AUTOSAR XML (schema 00044)
package /E40_Platform_System_SystemPackage/Components
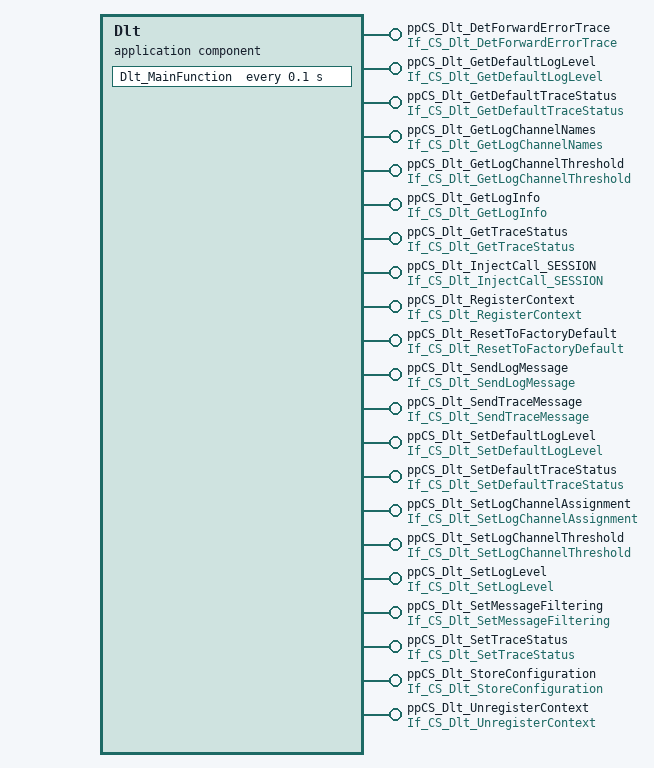
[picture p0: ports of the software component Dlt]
  application sw component type Dlt
    21 x provide port:
      ppCS_Dlt_DetForwardErrorTrace: server-com-spec{operation=DetForwardErrorTrace, queue-length=1}, provided-interface=If_CS_Dlt_DetForwardErrorTrace
      ppCS_Dlt_GetDefaultLogLevel: server-com-spec{operation=GetDefaultLogLevel, queue-length=1}, provided-interface=If_CS_Dlt_GetDefaultLogLevel
      ppCS_Dlt_GetDefaultTraceStatus: server-com-spec{operation=GetDefaultTraceStatus, queue-length=1}, provided-interface=If_CS_Dlt_GetDefaultTraceStatus
      ppCS_Dlt_GetLogChannelNames: server-com-spec{operation=GetLogChannelNames, queue-length=1}, provided-interface=If_CS_Dlt_GetLogChannelNames
      ppCS_Dlt_GetLogChannelThreshold: server-com-spec{operation=GetLogChannelThreshold, queue-length=1}, provided-interface=If_CS_Dlt_GetLogChannelThreshold
      ppCS_Dlt_GetLogInfo: server-com-spec{operation=GetLogInfo, queue-length=1}, provided-interface=If_CS_Dlt_GetLogInfo
      ppCS_Dlt_GetTraceStatus: server-com-spec{operation=GetTraceStatus, queue-length=1}, provided-interface=If_CS_Dlt_GetTraceStatus
      ppCS_Dlt_InjectCall_SESSION: server-com-spec{operation=InjectCall_SESSION, queue-length=1}, provided-interface=If_CS_Dlt_InjectCall_SESSION
      ppCS_Dlt_RegisterContext: server-com-spec{operation=RegisterContext, queue-length=1}, provided-interface=If_CS_Dlt_RegisterContext
      ppCS_Dlt_ResetToFactoryDefault: server-com-spec{operation=ResetToFactoryDefault, queue-length=1}, provided-interface=If_CS_Dlt_ResetToFactoryDefault
      ppCS_Dlt_SendLogMessage: server-com-spec{operation=SendLogMessage, queue-length=1}, provided-interface=If_CS_Dlt_SendLogMessage
      ppCS_Dlt_SendTraceMessage: server-com-spec{operation=SendTraceMessage, queue-length=1}, provided-interface=If_CS_Dlt_SendTraceMessage
      ppCS_Dlt_SetDefaultLogLevel: server-com-spec{operation=SetDefaultLogLevel, queue-length=1}, provided-interface=If_CS_Dlt_SetDefaultLogLevel
      ppCS_Dlt_SetDefaultTraceStatus: server-com-spec{operation=SetDefaultTraceStatus, queue-length=1}, provided-interface=If_CS_Dlt_SetDefaultTraceStatus
      ppCS_Dlt_SetLogChannelAssignment: server-com-spec{operation=SetLogChannelAssignment, queue-length=1}, provided-interface=If_CS_Dlt_SetLogChannelAssignment
      ppCS_Dlt_SetLogChannelThreshold: server-com-spec{operation=SetLogChannelThreshold, queue-length=1}, provided-interface=If_CS_Dlt_SetLogChannelThreshold
      ppCS_Dlt_SetLogLevel: server-com-spec{operation=SetLogLevel, queue-length=1}, provided-interface=If_CS_Dlt_SetLogLevel
      ppCS_Dlt_SetMessageFiltering: server-com-spec{operation=SetMessageFiltering, queue-length=1}, provided-interface=If_CS_Dlt_SetMessageFiltering
      ppCS_Dlt_SetTraceStatus: server-com-spec{operation=SetTraceStatus, queue-length=1}, provided-interface=If_CS_Dlt_SetTraceStatus
      ppCS_Dlt_StoreConfiguration: server-com-spec{operation=StoreConfiguration, queue-length=1}, provided-interface=If_CS_Dlt_StoreConfiguration
      ppCS_Dlt_UnregisterContext: server-com-spec{operation=UnregisterContext, queue-length=1}, provided-interface=If_CS_Dlt_UnregisterContext
    behavior IB_Dlt
      8 x operation invoked event:
        OIE_ppCS_Dlt_DetForwardErrorTrace_Dlt_DetForwardErrorTraceTrigByDetForwardErrorTrace: start-on-event=Dlt_DetForwardErrorTrace, operation=ppCS_Dlt_DetForwardErrorTrace.DetForwardErrorTrace
        OIE_ppCS_Dlt_GetDefaultLogLevel_Dlt_GetDefaultLogLevelTrigByGetDefaultLogLevel: start-on-event=Dlt_GetDefaultLogLevel, operation=ppCS_Dlt_GetDefaultLogLevel.GetDefaultLogLevel
        OIE_ppCS_Dlt_GetDefaultTraceStatus_Dlt_GetDefaultTraceStatusTrigByGetDefaultTraceStatus: start-on-event=Dlt_GetDefaultTraceStatus, operation=ppCS_Dlt_GetDefaultTraceStatus.GetDefaultTraceStatus
        OIE_ppCS_Dlt_GetLogChannelNames_Dlt_GetLogChannelNamesTrigByGetLogChannelNames: start-on-event=Dlt_GetLogChannelNames, operation=ppCS_Dlt_GetLogChannelNames.GetLogChannelNames
        OIE_ppCS_Dlt_GetLogChannelThreshold_Dlt_GetLogChannelThresholdTrigByGetLogChannelThreshold: start-on-event=Dlt_GetLogChannelThreshold, operation=ppCS_Dlt_GetLogChannelThreshold.GetLogChannelThreshold
        OIE_ppCS_Dlt_GetLogInfo_Dlt_GetLogInfoTrigByGetLogInfo: start-on-event=Dlt_GetLogInfo, operation=ppCS_Dlt_GetLogInfo.GetLogInfo
        OIE_ppCS_Dlt_GetTraceStatus_Dlt_GetTraceStatusTrigByGetTraceStatus: start-on-event=Dlt_GetTraceStatus, operation=ppCS_Dlt_GetTraceStatus.GetTraceStatus
        OIE_ppCS_Dlt_InjectCall_SESSION_Dlt_InjectCall_SESSIONTrigByInjectCall_SESSION: start-on-event=Dlt_InjectCall_SESSION, operation=ppCS_Dlt_InjectCall_SESSION.InjectCall_SESSION
      timing event TEDlt_MainFunction: start-on-event=Dlt_MainFunction, period=0.1
      13 x operation invoked event:
        OIE_ppCS_Dlt_RegisterContext_Dlt_RegisterContextTrigByRegisterContext: start-on-event=Dlt_RegisterContext, operation=ppCS_Dlt_RegisterContext.RegisterContext
        OIE_ppCS_Dlt_ResetToFactoryDefault_Dlt_ResetToFactoryDefaultTrigByResetToFactoryDefault: start-on-event=Dlt_ResetToFactoryDefault, operation=ppCS_Dlt_ResetToFactoryDefault.ResetToFactoryDefault
        OIE_ppCS_Dlt_SendLogMessage_Dlt_SendLogMessageTrigBySendLogMessage: start-on-event=Dlt_SendLogMessage, operation=ppCS_Dlt_SendLogMessage.SendLogMessage
        OIE_ppCS_Dlt_SendTraceMessage_Dlt_SendTraceMessageTrigBySendTraceMessage: start-on-event=Dlt_SendTraceMessage, operation=ppCS_Dlt_SendTraceMessage.SendTraceMessage
        OIE_ppCS_Dlt_SetDefaultLogLevel_Dlt_SetDefaultLogLevelTrigBySetDefaultLogLevel: start-on-event=Dlt_SetDefaultLogLevel, operation=ppCS_Dlt_SetDefaultLogLevel.SetDefaultLogLevel
        OIE_ppCS_Dlt_SetDefaultTraceStatus_Dlt_SetDefaultTraceStatusTrigBySetDefaultTraceStatus: start-on-event=Dlt_SetDefaultTraceStatus, operation=ppCS_Dlt_SetDefaultTraceStatus.SetDefaultTraceStatus
        OIE_ppCS_Dlt_SetLogChannelAssignment_Dlt_SetLogChannelAssignmentTrigBySetLogChannelAssignment: start-on-event=Dlt_SetLogChannelAssignment, operation=ppCS_Dlt_SetLogChannelAssignment.SetLogChannelAssignment
        OIE_ppCS_Dlt_SetLogChannelThreshold_Dlt_SetLogChannelThresholdTrigBySetLogChannelThreshold: start-on-event=Dlt_SetLogChannelThreshold, operation=ppCS_Dlt_SetLogChannelThreshold.SetLogChannelThreshold
        OIE_ppCS_Dlt_SetLogLevel_Dlt_SetLogLevelTrigBySetLogLevel: start-on-event=Dlt_SetLogLevel, operation=ppCS_Dlt_SetLogLevel.SetLogLevel
        OIE_ppCS_Dlt_SetMessageFiltering_Dlt_SetMessageFilteringTrigBySetMessageFiltering: start-on-event=Dlt_SetMessageFiltering, operation=ppCS_Dlt_SetMessageFiltering.SetMessageFiltering
        OIE_ppCS_Dlt_SetTraceStatus_Dlt_SetTraceStatusTrigBySetTraceStatus: start-on-event=Dlt_SetTraceStatus, operation=ppCS_Dlt_SetTraceStatus.SetTraceStatus
        OIE_ppCS_Dlt_StoreConfiguration_Dlt_StoreConfigurationTrigByStoreConfiguration: start-on-event=Dlt_StoreConfiguration, operation=ppCS_Dlt_StoreConfiguration.StoreConfiguration
        OIE_ppCS_Dlt_UnregisterContext_Dlt_UnregisterContextTrigByUnregisterContext: start-on-event=Dlt_UnregisterContext, operation=ppCS_Dlt_UnregisterContext.UnregisterContext
      port-api-options:
        enable-take-address=false, indirect-api=false, port=ppCS_Dlt_DetForwardErrorTrace
        enable-take-address=false, indirect-api=false, port=ppCS_Dlt_GetDefaultLogLevel
        enable-take-address=false, indirect-api=false, port=ppCS_Dlt_GetDefaultTraceStatus
        enable-take-address=false, indirect-api=false, port=ppCS_Dlt_GetLogChannelNames
        enable-take-address=false, indirect-api=false, port=ppCS_Dlt_GetLogChannelThreshold
        enable-take-address=false, indirect-api=false, port=ppCS_Dlt_GetLogInfo
        enable-take-address=false, indirect-api=false, port=ppCS_Dlt_GetTraceStatus
        enable-take-address=false, indirect-api=false, port=ppCS_Dlt_InjectCall_SESSION
        enable-take-address=false, indirect-api=false, port=ppCS_Dlt_RegisterContext
        enable-take-address=false, indirect-api=false, port=ppCS_Dlt_ResetToFactoryDefault
        enable-take-address=false, indirect-api=false, port=ppCS_Dlt_SendLogMessage
        enable-take-address=false, indirect-api=false, port=ppCS_Dlt_SendTraceMessage
        enable-take-address=false, indirect-api=false, port=ppCS_Dlt_SetDefaultLogLevel
        enable-take-address=false, indirect-api=false, port=ppCS_Dlt_SetDefaultTraceStatus
        enable-take-address=false, indirect-api=false, port=ppCS_Dlt_SetLogChannelAssignment
        enable-take-address=false, indirect-api=false, port=ppCS_Dlt_SetLogChannelThreshold
        enable-take-address=false, indirect-api=false, port=ppCS_Dlt_SetLogLevel
        enable-take-address=false, indirect-api=false, port=ppCS_Dlt_SetMessageFiltering
        enable-take-address=false, indirect-api=false, port=ppCS_Dlt_SetTraceStatus
        enable-take-address=false, indirect-api=false, port=ppCS_Dlt_StoreConfiguration
        enable-take-address=false, indirect-api=false, port=ppCS_Dlt_UnregisterContext
      22 x runnable, all with can-be-invoked-concurrently=true:
        Dlt_DetForwardErrorTrace
        Dlt_GetDefaultLogLevel
        Dlt_GetDefaultTraceStatus
        Dlt_GetLogChannelNames
        Dlt_GetLogChannelThreshold
        Dlt_GetLogInfo
        Dlt_GetTraceStatus
        Dlt_InjectCall_SESSION
        Dlt_MainFunction
        Dlt_RegisterContext
        Dlt_ResetToFactoryDefault
        Dlt_SendLogMessage
        Dlt_SendTraceMessage
        Dlt_SetDefaultLogLevel
        Dlt_SetDefaultTraceStatus
        Dlt_SetLogChannelAssignment
        Dlt_SetLogChannelThreshold
        Dlt_SetLogLevel
        Dlt_SetMessageFiltering
        Dlt_SetTraceStatus
        Dlt_StoreConfiguration
        Dlt_UnregisterContext
  swc implementation IMPL_Dlt: behavior=IB_Dlt
